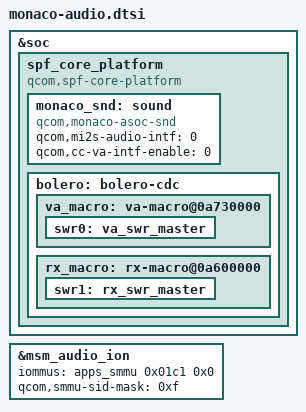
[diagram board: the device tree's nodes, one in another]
#include <dt-bindings/clock/qcom,audio-ext-clk.h>
#include "msm-audio-lpass.dtsi"

&soc {
	spf_core_platform: spf_core_platform {
		compatible = "qcom,spf-core-platform";
	};
};

#include "monaco-lpi.dtsi"

&spf_core_platform {
	monaco_snd: sound {
		compatible = "qcom,monaco-asoc-snd";
		qcom,mi2s-audio-intf = <0>;
		qcom,cc-va-intf-enable = <0>;
	};

	bolero: bolero-cdc {
		va_macro: va-macro@0a730000 {
			swr0: va_swr_master {
			};
		};

		rx_macro: rx-macro@0a600000 {
			swr1: rx_swr_master {
			};
		};
	};
};

&msm_audio_ion {
	iommus = <&apps_smmu 0x01c1 0x0>;
	qcom,smmu-sid-mask = /bits/ 64 <0xf>;
};
